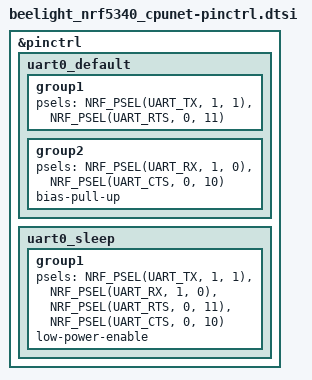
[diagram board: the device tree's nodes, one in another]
/*
 * Copyright (c) 2025 Daniel Kampert
 *
 * SPDX-License-Identifier: Apache-2.0
 */

&pinctrl {
    uart0_default: uart0_default {
        group1 {
            psels = <NRF_PSEL(UART_TX, 1, 1)>,
                    <NRF_PSEL(UART_RTS, 0, 11)>;
        };
        group2 {
            psels = <NRF_PSEL(UART_RX, 1, 0)>,
                    <NRF_PSEL(UART_CTS, 0, 10)>;
            bias-pull-up;
        };
    };

    uart0_sleep: uart0_sleep {
        group1 {
            psels = <NRF_PSEL(UART_TX, 1, 1)>,
                    <NRF_PSEL(UART_RX, 1, 0)>,
                    <NRF_PSEL(UART_RTS, 0, 11)>,
                    <NRF_PSEL(UART_CTS, 0, 10)>;
            low-power-enable;
        };
    };
};
